# LPC111x_LPC11Cxx register map
File version: 6
CPU: CM0 r0p0, little endian, no MPU, no FPU, 2 interrupt priority bits
Registers are 32-bit, read-write, reset 0x0 unless marked. A register's access mark holds for its fields unless they carry their own. Offsets are from the block's base; [hi:lo] are bit positions; {n}, {i} and the like mark numbered series.

## PMU — power management unit
Base 0x40038000
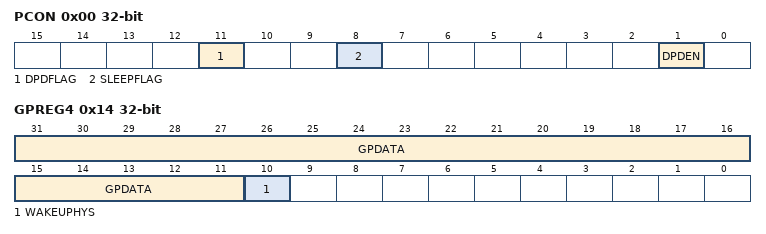
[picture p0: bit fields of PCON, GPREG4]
0x00 PCON — Power control register
  [11] DPDFLAG — Deep power-down flag
    0=NODEEPPOWERDOWN (Read: Deep power-down mode not entered. Write: No effect.); 1=DEEPPOWERDOWN (Read: Deep power-down mode entered. Write: Clear the Deep power-down flag.)
  [8] SLEEPFLAG — Sleep mode flag
    0=NOPOWERDOWN (Read: No power-down mode entered. LPC111x/LPC11C1x is in Active mode. Write: No effect.); 1=POWERDOWN (Read: Sleep/Deep-sleep or Deep power-down mode entered. Write: Writing a 1 clears the SLEEPFLAG bit to 0.)
  [1] DPDEN — Deep power-down mode enable
    0=SLEEPMODE (ARM WFI will enter Sleep or Deep-sleep mode (clock to ARM Cortex-M0 core turned off).); 1=DEEPPOWERDOWN (ARM WFI will enter Deep-power down mode (ARM Cortex-M0 core powered-down).)
{0x4+4i} GPREG{i} (i=0..3) — General purpose register
  [31:0] GPDATA — Data retained during Deep power-down mode.
0x14 GPREG4 — General purpose register 4
  [31:11] GPDATA — Data retained during Deep power-down mode.
  [10] WAKEUPHYS — WAKEUP pin hysteresis enable
    1=ENABLED (Hysteresis for WAKEUP pin enabled.); 0=DISABLED (Hysteresis for WAKUP pin disabled.)

## FLASHCTRL — Product name title=UM10462 Chapter title=LPC11U1x Flash programming firmware Modification date=3/17/2011 Major revision=0 Minor revision=3
Base 0x4003C000
0x10 FLASHCFG reset not defined — Flash memory access time configuration register
  [1:0] FLASHTIM — Flash memory access time. FLASHTIM +1 is equal to the number of system clocks used for flash access.
    1=1_SYSTEM_CLOCK_FLASH (1 system clock flash access time (for system clock frequencies of up to 20 MHz).); 2=2_SYSTEM_CLOCKS_FLAS (2 system clocks flash access time (for system clock frequencies of up to 40 MHz).); 3=3_SYSTEM_CLOCKS_FLAS (3 system clocks flash access time (for system clock frequencies of up to 50 MHz).)
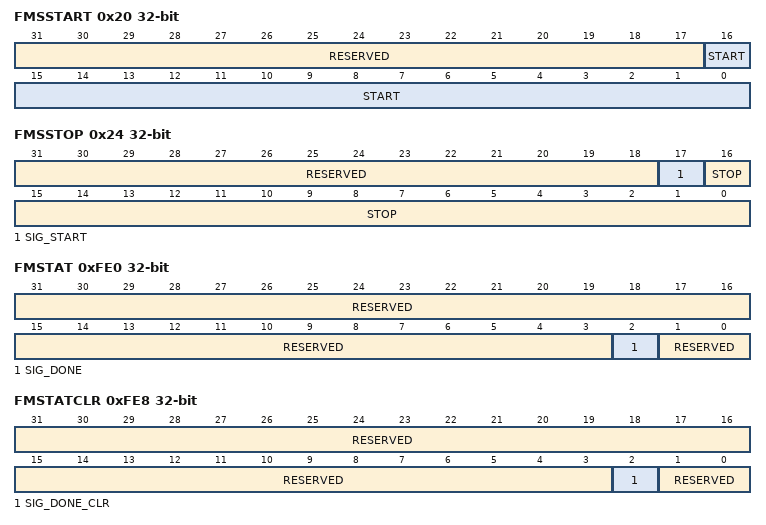
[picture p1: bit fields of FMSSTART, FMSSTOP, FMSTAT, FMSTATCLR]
0x20 FMSSTART — Signature start address register
  [31:17] RESERVED — Reserved, user software should not write ones to reserved bits. The value read from a reserved bit is not defined.
  [16:0] START — Signature generation start address (corresponds to AHB byte address bits[20:4]).
0x24 FMSSTOP — Signature stop-address register
  [31:18] RESERVED — Reserved, user software should not write ones to reserved bits. The value read from a reserved bit is not defined.
  [17] SIG_START — Start control bit for signature generation.
    0=SIGNATURE_GENERATION (Signature generation is stopped); 1=INITIATE_SIGNATURE_G (Initiate signature generation)
  [16:0] STOP — BIST stop address divided by 16 (corresponds to AHB byte address [20:4]).
{0x2C+4i} FMSW{i} ro reset not defined (i=0..3) — Word {i} [{32i+31}:{32i}]
  [31:0] SW{i}_{32i+31}_{32i} — Word {i} of 128-bit signature (bits {32i+31} to {32i}).
0xFE0 FMSTAT ro — Signature generation status register
  [31:3] RESERVED — Reserved, user software should not write ones to reserved bits. The value read from a reserved bit is not defined.
  [2] SIG_DONE — When 1, a previously started signature generation has completed. See FMSTATCLR register description for clearing this flag.
  [1:0] RESERVED — Reserved, user software should not write ones to reserved bits. The value read from a reserved bit is not defined.
0xFE8 FMSTATCLR wo reset not defined — Signature generation status clear register
  [31:3] RESERVED — Reserved, user software should not write ones to reserved bits. The value read from a reserved bit is not defined.
  [2] SIG_DONE_CLR — Writing a 1 to this bits clears the signature generation completion flag (SIG_DONE) in the FMSTAT register.
  [1:0] RESERVED — Reserved, user software should not write ones to reserved bits. The value read from a reserved bit is not defined.

## GPIO0
Base 0x50000000
Same registers: GPIO1 0x50010000, GPIO2 0x50020000, GPIO3 0x50030000
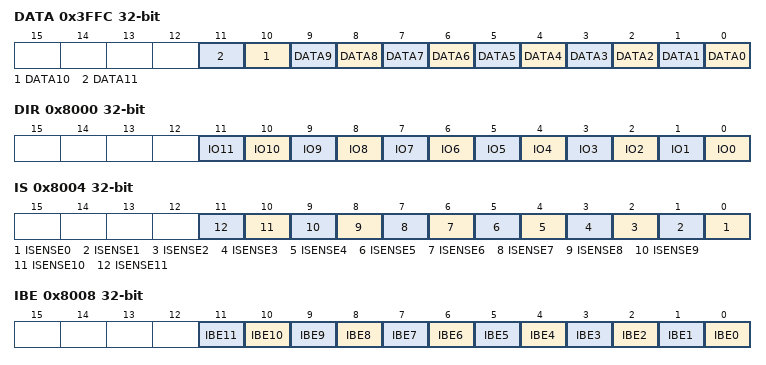
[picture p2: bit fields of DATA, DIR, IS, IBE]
0x3FFC DATA reset not defined — Port n data register for pins PIOn_0 to PIOn_11
  [n] DATA{n} (n=0..11) — Logic levels for pins PIOn_0 to PIOn_11. HIGH = 1, LOW = 0.
0x8000 DIR — Data direction register for port n
  [n] IO{n} (n=0..11) — Selects pin x as input or output (x = 0 to 11). 0 = Pin PIOn_x is configured as input. 1 = Pin PIOn_x is configured as output.
0x8004 IS — Interrupt sense register for port n
  [n] ISENSE{n} (n=0..11) — Selects interrupt on pin x as level or edge sensitive (x = 0 to 11). 0 = Interrupt on pin PIOn_x is configured as edge sensitive. 1 = Interrupt on pin PIOn_x is configured as level sensitive.
0x8008 IBE — Interrupt both edges register for port n
  [n] IBE{n} (n=0..11) — Selects interrupt on pin x to be triggered on both edges (x = 0 to 11). 0 = Interrupt on pin PIOn_x is controlled through register GPIOnIEV. 1 = Both edges on pin PIOn_x trigger an interrupt.
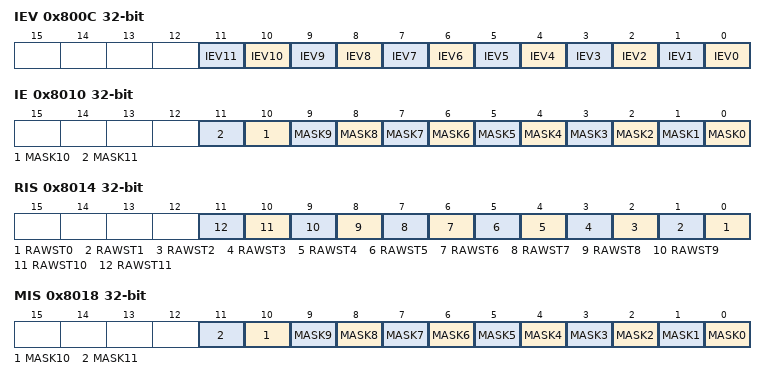
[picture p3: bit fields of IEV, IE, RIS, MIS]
0x800C IEV — Interrupt event register for port n
  [n] IEV{n} (n=0..11) — Selects interrupt on pin x to be triggered rising or falling edges (x = 0 to 11). 0 = Depending on setting in register GPIOnIS (see Table 109), falling edges or LOW level on pin PIOn_x trigger an interrupt. 1 = Depending on setting in register GPIOnIS (see Table 109), rising edges or HIGH level on pin PIOn_x trigger an interrupt.
0x8010 IE — Interrupt mask register for port n
  [n] MASK{n} (n=0..11) — Selects interrupt on pin x to be masked (x = 0 to 11). 0 = Interrupt on pin PIOn_x is masked. 1 = Interrupt on pin PIOn_x is not masked.
0x8014 RIS ro — Raw interrupt status register for port n
  [n] RAWST{n} (n=0..11) — Raw interrupt status (x = 0 to 11). 0 = No interrupt on pin PIOn_x. 1 = Interrupt requirements met on PIOn_x.
0x8018 MIS ro — Masked interrupt status register for port n
  [n] MASK{n} (n=0..11) — Selects interrupt on pin x to be masked (x = 0 to 11). 0 = No interrupt or interrupt masked on pin PIOn_x. 1 = Interrupt on PIOn_x.
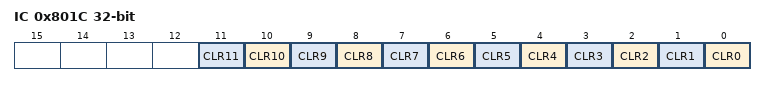
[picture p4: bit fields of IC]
0x801C IC wo — Interrupt clear register for port n
  [n] CLR{n} (n=0..11) — Selects interrupt on pin x to be cleared (x = 0 to 11). Clears the interrupt edge detection logic. This register is write-only. The synchronizer between the GPIO and the NVIC blocks causes a delay of 2 clocks. It is recommended to add two NOPs after the clear of the interrupt edge detection logic before the exit of the interrupt service routine. 0 = No effect. 1 = Clears edge detection logic for pin PIOn_x.
